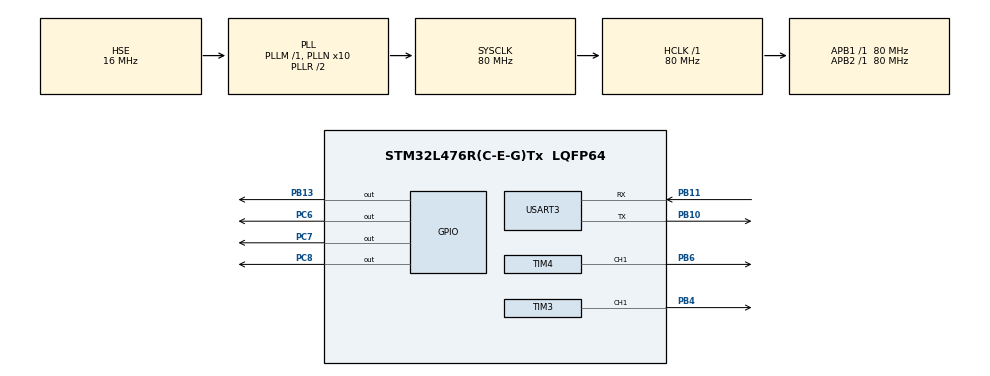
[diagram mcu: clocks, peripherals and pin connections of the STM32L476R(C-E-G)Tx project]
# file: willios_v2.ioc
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Mcu.Family=STM32L4
Dma.TIM4_CH1.1.MemDataAlignment=DMA_MDATAALIGN_HALFWORD
Dma.TIM4_CH1.1.PeriphDataAlignment=DMA_PDATAALIGN_HALFWORD
RCC.CortexFreq_Value=80000000
PB10.Mode=Asynchronous
PH0-OSC_IN\ (PH0).Signal=RCC_OSC_IN
Dma.TIM3_CH1/TRIG.0.MemDataAlignment=DMA_MDATAALIGN_HALFWORD
PB11.Signal=USART3_RX
PB13.Signal=GPIO_Output
RCC.SYSCLKSource=RCC_SYSCLKSOURCE_PLLCLK
ProjectManager.StackSize=0x400
USART3.VirtualMode-Asynchronous=VM_ASYNC
PA14\ (JTCK-SWCLK).Signal=SYS_JTCK-SWCLK
RCC.HCLKFreq_Value=80000000
RCC.APB2TimFreq_Value=80000000
TIM3.Period=100 - 1
PB6.Signal=S_TIM4_CH1
PC7.Signal=GPIO_Output
RCC.AHBFreq_Value=80000000
RCC.PREFETCH_ENABLE=1
TIM3.Channel-PWM\ Generation1\ CH1=TIM_CHANNEL_1
PH1-OSC_OUT\ (PH1).Mode=HSE-External-Oscillator
RCC.HSE_VALUE=16000000
Dma.TIM4_CH1.1.MemInc=DMA_MINC_ENABLE
Dma.TIM3_CH1/TRIG.0.PeriphDataAlignment=DMA_PDATAALIGN_HALFWORD
Dma.TIM3_CH1/TRIG.0.Priority=DMA_PRIORITY_LOW
SH.S_TIM3_CH1.0=TIM3_CH1,PWM Generation1 CH1
TIM4.Period=100-1
Mcu.Package=LQFP64
SH.S_TIM4_CH1.0=TIM4_CH1,PWM Generation1 CH1
Dma.Request1=TIM4_CH1
RCC.APB1TimFreq_Value=80000000
PA13\ (JTMS-SWDIO).Signal=SYS_JTMS-SWDIO
Dma.Request0=TIM3_CH1/TRIG
PH0-OSC_IN\ (PH0).Mode=HSE-External-Oscillator
Dma.TIM4_CH1.1.PeriphInc=DMA_PINC_DISABLE
RCC.MSI_VALUE=4000000
RCC.PLLSourceVirtual=RCC_PLLSOURCE_HSE
TIM4.Channel-PWM\ Generation1\ CH1=TIM_CHANNEL_1
PA14\ (JTCK-SWCLK).Mode=Serial_Wire
NVIC.DMA1_Channel6_IRQn=true\:0\:0\:false\:false\:true\:false\:true
Dma.TIM3_CH1/TRIG.0.PeriphInc=DMA_PINC_DISABLE
PC8.Signal=GPIO_Output
PC6.Signal=GPIO_Output
Dma.TIM3_CH1/TRIG.0.MemInc=DMA_MINC_ENABLE
PA14\ (JTCK-SWCLK).GPIO_Label=TCK
PH1-OSC_OUT\ (PH1).Signal=RCC_OSC_OUT
PB11.Mode=Asynchronous
ProjectManager.TargetToolchain=STM32CubeIDE
RCC.USBFreq_Value=64000000
RCC.LSE_VALUE=32768
PB10.Signal=USART3_TX
Dma.TIM4_CH1.1.Instance=DMA1_Channel1
board=NUCLEO-L476RG
RCC.VCOOutputFreq_Value=160000000
Dma.TIM4_CH1.1.Direction=DMA_MEMORY_TO_PERIPH
RCC.APB2Freq_Value=80000000
PA13\ (JTMS-SWDIO).GPIO_Label=TMS
RCC.ADCFreq_Value=64000000
Dma.TIM4_CH1.1.Mode=DMA_NORMAL
Mcu.Name=STM32L476R(C-E-G)Tx
Dma.TIM3_CH1/TRIG.0.Mode=DMA_NORMAL
PA13\ (JTMS-SWDIO).Mode=Serial_Wire
RCC.SYSCLKFreq_VALUE=80000000
Dma.TIM3_CH1/TRIG.0.Direction=DMA_MEMORY_TO_PERIPH
ProjectManager.HeapSize=0x200
RCC.HSI_VALUE=16000000
NVIC.PriorityGroup=NVIC_PRIORITYGROUP_4
Dma.TIM3_CH1/TRIG.0.Instance=DMA1_Channel6
RCC.PLLN=10
NVIC.DMA1_Channel1_IRQn=true\:0\:0\:false\:false\:true\:false\:true
RCC.APB1Freq_Value=80000000
Dma.TIM4_CH1.1.Priority=DMA_PRIORITY_LOW
PB4\ (NJTRST).Signal=S_TIM3_CH1

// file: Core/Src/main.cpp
/* USER CODE BEGIN Header */
/**
  ******************************************************************************
  * @file           : main.c
  * @brief          : Main program body
  ******************************************************************************
  * @attention
  *
  * <h2><center>&copy; Copyright (c) 2021 STMicroelectronics.
  * All rights reserved.</center></h2>
  *
  * This software component is licensed by ST under BSD 3-Clause license,
  * the "License"; You may not use this file except in compliance with the
  * License. You may obtain a copy of the License at:
  *                        opensource.org/licenses/BSD-3-Clause
  *
  ******************************************************************************
  */
/* USER CODE END Header */
#include "main.h"

/* USER CODE BEGIN Includes */
#include "ws2812b.h"
/* USER CODE END Includes */

TIM_HandleTypeDef htim3;
TIM_HandleTypeDef htim4;
DMA_HandleTypeDef hdma_tim3_ch1_trig;
DMA_HandleTypeDef hdma_tim4_ch1;

UART_HandleTypeDef huart3;

/* USER CODE BEGIN PV */
WS2812B ws2812b(FCPU_HZ, WS2812B_LED_COUNT, &htim3);
/* USER CODE END PV */

void SystemClock_Config(void);
static void MX_GPIO_Init(void);
static void MX_DMA_Init(void);
static void MX_USART3_UART_Init(void);
static void MX_TIM3_Init(void);
static void MX_TIM4_Init(void);

int main(void)
{

  /* MCU Configuration--------------------------------------------------------*/

  /* Reset of all peripherals, Initializes the Flash interface and the Systick. */
  HAL_Init();

  /* Configure the system clock */
  SystemClock_Config();

  /* Initialize all configured peripherals */
  MX_GPIO_Init();
  MX_DMA_Init();
  MX_USART3_UART_Init();
  MX_TIM3_Init();
  MX_TIM4_Init();
  /* USER CODE BEGIN 2 */
	//ws2812b.send(255, 0, 0);

  /* USER CODE END 2 */

  /* Infinite loop */
  while (1)
  {

    /* USER CODE BEGIN 3 */
  	HAL_GPIO_TogglePin(GPIOB, GPIO_PIN_13);
  	HAL_GPIO_TogglePin(GPIOC, GPIO_PIN_8);
  	HAL_GPIO_TogglePin(GPIOC, GPIO_PIN_7);
  	HAL_GPIO_TogglePin(GPIOC, GPIO_PIN_6);
  	HAL_Delay(500);

  	ws2812b.setColor(0, 0, 255, 0);
  	ws2812b.setColor(1, 255, 255, 0);
  	ws2812b.setColor(2, 255, 0, 0);

  	ws2812b.setBrightness(1);
  	ws2812b.update();

  }
  /* USER CODE END 3 */
}

void SystemClock_Config(void)
{
  RCC_OscInitTypeDef RCC_OscInitStruct = {0};
  RCC_ClkInitTypeDef RCC_ClkInitStruct = {0};
  RCC_PeriphCLKInitTypeDef PeriphClkInit = {0};

  /** Initializes the RCC Oscillators according to the specified parameters
  * in the RCC_OscInitTypeDef structure.
  */
  RCC_OscInitStruct.OscillatorType = RCC_OSCILLATORTYPE_HSE;
  RCC_OscInitStruct.HSEState = RCC_HSE_ON;
  RCC_OscInitStruct.PLL.PLLState = RCC_PLL_ON;
  RCC_OscInitStruct.PLL.PLLSource = RCC_PLLSOURCE_HSE;
  RCC_OscInitStruct.PLL.PLLM = 1;
  RCC_OscInitStruct.PLL.PLLN = 10;
  RCC_OscInitStruct.PLL.PLLP = RCC_PLLP_DIV7;
  RCC_OscInitStruct.PLL.PLLQ = RCC_PLLQ_DIV2;
  RCC_OscInitStruct.PLL.PLLR = RCC_PLLR_DIV2;
  if (HAL_RCC_OscConfig(&RCC_OscInitStruct) != HAL_OK)
  {
    Error_Handler();
  }
  /** Initializes the CPU, AHB and APB buses clocks
  */
  RCC_ClkInitStruct.ClockType = RCC_CLOCKTYPE_HCLK|RCC_CLOCKTYPE_SYSCLK
                              |RCC_CLOCKTYPE_PCLK1|RCC_CLOCKTYPE_PCLK2;
  RCC_ClkInitStruct.SYSCLKSource = RCC_SYSCLKSOURCE_PLLCLK;
  RCC_ClkInitStruct.AHBCLKDivider = RCC_SYSCLK_DIV1;
  RCC_ClkInitStruct.APB1CLKDivider = RCC_HCLK_DIV1;
  RCC_ClkInitStruct.APB2CLKDivider = RCC_HCLK_DIV1;

  if (HAL_RCC_ClockConfig(&RCC_ClkInitStruct, FLASH_LATENCY_4) != HAL_OK)
  {
    Error_Handler();
  }
  PeriphClkInit.PeriphClockSelection = RCC_PERIPHCLK_USART3;
  PeriphClkInit.Usart3ClockSelection = RCC_USART3CLKSOURCE_PCLK1;
  if (HAL_RCCEx_PeriphCLKConfig(&PeriphClkInit) != HAL_OK)
  {
    Error_Handler();
  }
  /** Configure the main internal regulator output voltage
  */
  if (HAL_PWREx_ControlVoltageScaling(PWR_REGULATOR_VOLTAGE_SCALE1) != HAL_OK)
  {
    Error_Handler();
  }
}

static void MX_TIM3_Init(void)
{

  TIM_MasterConfigTypeDef sMasterConfig = {0};
  TIM_OC_InitTypeDef sConfigOC = {0};

  htim3.Instance = TIM3;
  htim3.Init.Prescaler = 0;
  htim3.Init.CounterMode = TIM_COUNTERMODE_UP;
  htim3.Init.Period = 100-1;
  htim3.Init.ClockDivision = TIM_CLOCKDIVISION_DIV1;
  htim3.Init.AutoReloadPreload = TIM_AUTORELOAD_PRELOAD_DISABLE;
  if (HAL_TIM_PWM_Init(&htim3) != HAL_OK)
  {
    Error_Handler();
  }
  sMasterConfig.MasterOutputTrigger = TIM_TRGO_RESET;
  sMasterConfig.MasterSlaveMode = TIM_MASTERSLAVEMODE_DISABLE;
  if (HAL_TIMEx_MasterConfigSynchronization(&htim3, &sMasterConfig) != HAL_OK)
  {
    Error_Handler();
  }
  sConfigOC.OCMode = TIM_OCMODE_PWM1;
  sConfigOC.Pulse = 0;
  sConfigOC.OCPolarity = TIM_OCPOLARITY_HIGH;
  sConfigOC.OCFastMode = TIM_OCFAST_DISABLE;
  if (HAL_TIM_PWM_ConfigChannel(&htim3, &sConfigOC, TIM_CHANNEL_1) != HAL_OK)
  {
    Error_Handler();
  }
  HAL_TIM_MspPostInit(&htim3);

}

static void MX_TIM4_Init(void)
{

  TIM_MasterConfigTypeDef sMasterConfig = {0};
  TIM_OC_InitTypeDef sConfigOC = {0};

  htim4.Instance = TIM4;
  htim4.Init.Prescaler = 0;
  htim4.Init.CounterMode = TIM_COUNTERMODE_UP;
  htim4.Init.Period = 100-1;
  htim4.Init.ClockDivision = TIM_CLOCKDIVISION_DIV1;
  htim4.Init.AutoReloadPreload = TIM_AUTORELOAD_PRELOAD_DISABLE;
  if (HAL_TIM_PWM_Init(&htim4) != HAL_OK)
  {
    Error_Handler();
  }
  sMasterConfig.MasterOutputTrigger = TIM_TRGO_RESET;
  sMasterConfig.MasterSlaveMode = TIM_MASTERSLAVEMODE_DISABLE;
  if (HAL_TIMEx_MasterConfigSynchronization(&htim4, &sMasterConfig) != HAL_OK)
  {
    Error_Handler();
  }
  sConfigOC.OCMode = TIM_OCMODE_PWM1;
  sConfigOC.Pulse = 0;
  sConfigOC.OCPolarity = TIM_OCPOLARITY_HIGH;
  sConfigOC.OCFastMode = TIM_OCFAST_DISABLE;
  if (HAL_TIM_PWM_ConfigChannel(&htim4, &sConfigOC, TIM_CHANNEL_1) != HAL_OK)
  {
    Error_Handler();
  }
  HAL_TIM_MspPostInit(&htim4);

}

static void MX_USART3_UART_Init(void)
{

  huart3.Instance = USART3;
  huart3.Init.BaudRate = 115200;
  huart3.Init.WordLength = UART_WORDLENGTH_8B;
  huart3.Init.StopBits = UART_STOPBITS_1;
  huart3.Init.Parity = UART_PARITY_NONE;
  huart3.Init.Mode = UART_MODE_TX_RX;
  huart3.Init.HwFlowCtl = UART_HWCONTROL_NONE;
  huart3.Init.OverSampling = UART_OVERSAMPLING_16;
  huart3.Init.OneBitSampling = UART_ONE_BIT_SAMPLE_DISABLE;
  huart3.AdvancedInit.AdvFeatureInit = UART_ADVFEATURE_NO_INIT;
  if (HAL_UART_Init(&huart3) != HAL_OK)
  {
    Error_Handler();
  }

}

static void MX_DMA_Init(void)
{

  /* DMA controller clock enable */
  __HAL_RCC_DMA1_CLK_ENABLE();

  /* DMA interrupt init */
  /* DMA1_Channel1_IRQn interrupt configuration */
  HAL_NVIC_SetPriority(DMA1_Channel1_IRQn, 0, 0);
  HAL_NVIC_EnableIRQ(DMA1_Channel1_IRQn);
  /* DMA1_Channel6_IRQn interrupt configuration */
  HAL_NVIC_SetPriority(DMA1_Channel6_IRQn, 0, 0);
  HAL_NVIC_EnableIRQ(DMA1_Channel6_IRQn);

}

static void MX_GPIO_Init(void)
{
  GPIO_InitTypeDef GPIO_InitStruct = {0};

  /* GPIO Ports Clock Enable */
  __HAL_RCC_GPIOH_CLK_ENABLE();
  __HAL_RCC_GPIOB_CLK_ENABLE();
  __HAL_RCC_GPIOC_CLK_ENABLE();
  __HAL_RCC_GPIOA_CLK_ENABLE();

  /*Configure GPIO pin Output Level */
  HAL_GPIO_WritePin(GPIOB, GPIO_PIN_13, GPIO_PIN_RESET);

  /*Configure GPIO pin Output Level */
  HAL_GPIO_WritePin(GPIOC, GPIO_PIN_6|GPIO_PIN_7|GPIO_PIN_8, GPIO_PIN_RESET);

  /*Configure GPIO pin : PB13 */
  GPIO_InitStruct.Pin = GPIO_PIN_13;
  GPIO_InitStruct.Mode = GPIO_MODE_OUTPUT_PP;
  GPIO_InitStruct.Pull = GPIO_NOPULL;
  GPIO_InitStruct.Speed = GPIO_SPEED_FREQ_LOW;
  HAL_GPIO_Init(GPIOB, &GPIO_InitStruct);

  /*Configure GPIO pins : PC6 PC7 PC8 */
  GPIO_InitStruct.Pin = GPIO_PIN_6|GPIO_PIN_7|GPIO_PIN_8;
  GPIO_InitStruct.Mode = GPIO_MODE_OUTPUT_PP;
  GPIO_InitStruct.Pull = GPIO_NOPULL;
  GPIO_InitStruct.Speed = GPIO_SPEED_FREQ_LOW;
  HAL_GPIO_Init(GPIOC, &GPIO_InitStruct);

}

void Error_Handler(void)
{
  __disable_irq();
  while (1)
  {
  }
}

/************************ (C) COPYRIGHT STMicroelectronics *****END OF FILE****/
